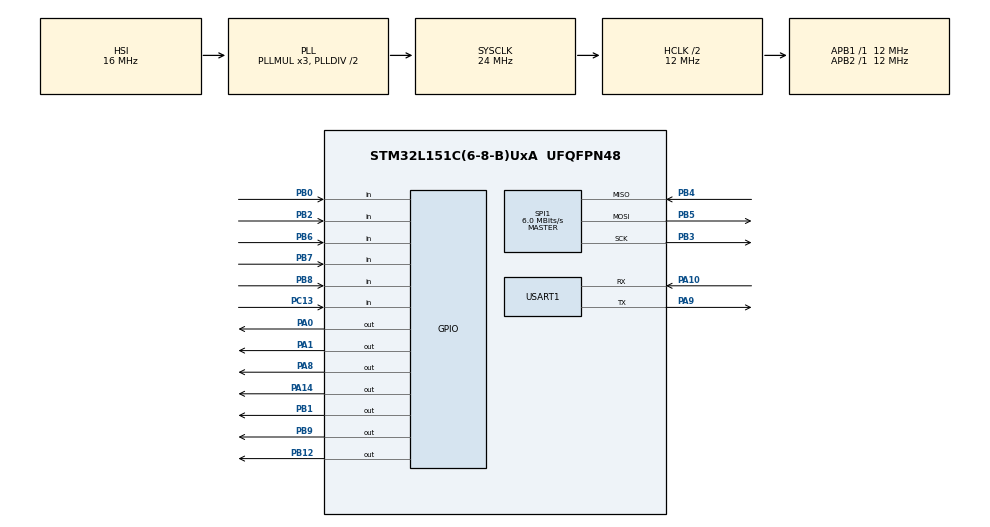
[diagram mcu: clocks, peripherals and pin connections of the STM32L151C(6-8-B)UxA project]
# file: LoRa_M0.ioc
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Dma.Request0=USART1_RX
Dma.USART1_RX.0.Direction=DMA_PERIPH_TO_MEMORY
Dma.USART1_RX.0.Instance=DMA1_Channel5
Dma.USART1_RX.0.MemDataAlignment=DMA_MDATAALIGN_BYTE
Dma.USART1_RX.0.MemInc=DMA_MINC_ENABLE
Dma.USART1_RX.0.Mode=DMA_NORMAL
Dma.USART1_RX.0.PeriphDataAlignment=DMA_PDATAALIGN_BYTE
Dma.USART1_RX.0.PeriphInc=DMA_PINC_DISABLE
Dma.USART1_RX.0.Priority=DMA_PRIORITY_LOW
Mcu.Family=STM32L1
Mcu.Name=STM32L151C(6-8-B)UxA
Mcu.Package=UFQFPN48
NVIC.DMA1_Channel5_IRQn=true\:0\:0\:false\:false\:true\:false\:true
NVIC.PriorityGroup=NVIC_PRIORITYGROUP_4
PA0-WKUP1.Signal=GPIO_Output
PA1.Signal=GPIO_Output
PA10.Mode=Asynchronous
PA10.Signal=USART1_RX
PA14.Signal=GPIO_Output
PA8.Signal=GPIO_Output
PA9.Mode=Asynchronous
PA9.Signal=USART1_TX
PB0.Signal=GPIO_Input
PB1.Signal=GPIO_Output
PB12.Signal=GPIO_Output
PB2.Signal=GPIO_Input
PB3.Mode=Full_Duplex_Master
PB3.Signal=SPI1_SCK
PB4.Mode=Full_Duplex_Master
PB4.Signal=SPI1_MISO
PB5.Mode=Full_Duplex_Master
PB5.Signal=SPI1_MOSI
PB6.Signal=GPIO_Input
PB7.Signal=GPIO_Input
PB8.Signal=GPIO_Input
PB9.GPIO_Speed=GPIO_SPEED_FREQ_LOW
PB9.Signal=GPIO_Output
PC13-WKUP2.Signal=GPIO_Input
ProjectManager.HeapSize=0x200
ProjectManager.StackSize=0x400
ProjectManager.TargetToolchain=EWARM V8
RCC.AHBCLKDivider=RCC_SYSCLK_DIV2
RCC.AHBFreq_Value=12000000
RCC.APB1Freq_Value=12000000
RCC.APB1TimFreq_Value=12000000
RCC.APB2Freq_Value=12000000
RCC.APB2TimFreq_Value=12000000
RCC.HCLKFreq_Value=12000000
RCC.HSE_VALUE=24000000
RCC.HSI_VALUE=16000000
RCC.LSE_VALUE=32768
RCC.MSIClockRange=RCC_MSIRANGE_6
RCC.MSI_VALUE=4194000
RCC.SYSCLKFreq_VALUE=24000000
RCC.SYSCLKSource=RCC_SYSCLKSOURCE_PLLCLK
RCC.VCOOutputFreq_Value=48000000
SPI1.BaudRatePrescaler=SPI_BAUDRATEPRESCALER_2
SPI1.CalculateBaudRate=6.0 MBits/s
SPI1.Direction=SPI_DIRECTION_2LINES
SPI1.Mode=SPI_MODE_MASTER
SPI1.VirtualType=VM_MASTER
USART1.VirtualMode=VM_ASYNC
board=custom

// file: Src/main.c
/* USER CODE BEGIN Header */
/**
  ******************************************************************************
  * @file           : main.c
  * @brief          : Main program body
  ******************************************************************************
  * @attention
  *
  * <h2><center>&copy; Copyright (c) 2019 STMicroelectronics.
  * All rights reserved.</center></h2>
  *
  * This software component is licensed by ST under BSD 3-Clause license,
  * the "License"; You may not use this file except in compliance with the
  * License. You may obtain a copy of the License at:
  *                        opensource.org/licenses/BSD-3-Clause
  *
  ******************************************************************************
  */
/* USER CODE END Header */

#include "main.h"
#include "dma.h"
#include "spi.h"
#include "usart.h"
#include "gpio.h"
#include <stdio.h>

//sx1278
#include "radio.h"
#include "platform.h"
#include "sx1276-Hal.h"
#include "sx1276-LoRa.h"
#include "sx1276-LoRaMisc.h"

void SystemClock_Config(void);

int main(void)
{
  /* USER CODE BEGIN 1 */
  uint8_t RegVersion = 0;

  /* USER CODE END 1 */

  /* MCU Configuration--------------------------------------------------------*/

  /* Reset of all peripherals, Initializes the Flash interface and the Systick. */
  HAL_Init();

  /* Configure the system clock */
  SystemClock_Config();

  /* Initialize all configured peripherals */
  MX_GPIO_Init();
  MX_DMA_Init();
 // printf("haha");
  MX_SPI1_Init();
  MX_USART1_UART_Init();

  /* Infinite loop */
  /* USER CODE BEGIN WHILE */

//-----------------------------------------------------------
  HAL_GPIO_WritePin(GPIOA, GPIO_PIN_1, GPIO_PIN_RESET);
//  printf("LoRa Test1\r\n");

  SX1276Read( REG_LR_VERSION, &RegVersion );
  if(RegVersion == 0x12)
  {
    printf("LoRa read OK\r\n");
    printf("LoRa RegVersion = %d\r\n", RegVersion);
  }
  else
  {
    printf("LoRa read ERROR\r\n");
    printf("LoRa RegVersion = %d\r\n", RegVersion);
  }

//-----------------------------------------------------------
  while (1)
  {
    /* USER CODE END WHILE */

  }
}

void SystemClock_Config(void)
{
  RCC_OscInitTypeDef RCC_OscInitStruct = {0};
  RCC_ClkInitTypeDef RCC_ClkInitStruct = {0};

  /** Configure the main internal regulator output voltage
  */
  __HAL_PWR_VOLTAGESCALING_CONFIG(PWR_REGULATOR_VOLTAGE_SCALE1);
  /** Initializes the CPU, AHB and APB busses clocks
  */
  RCC_OscInitStruct.OscillatorType = RCC_OSCILLATORTYPE_HSI;
  RCC_OscInitStruct.HSIState = RCC_HSI_ON;
  RCC_OscInitStruct.HSICalibrationValue = RCC_HSICALIBRATION_DEFAULT;
  RCC_OscInitStruct.PLL.PLLState = RCC_PLL_ON;
  RCC_OscInitStruct.PLL.PLLSource = RCC_PLLSOURCE_HSI;
  RCC_OscInitStruct.PLL.PLLMUL = RCC_PLL_MUL3;
  RCC_OscInitStruct.PLL.PLLDIV = RCC_PLL_DIV2;
  if (HAL_RCC_OscConfig(&RCC_OscInitStruct) != HAL_OK)
  {
    Error_Handler();
  }
  /** Initializes the CPU, AHB and APB busses clocks
  */
  RCC_ClkInitStruct.ClockType = RCC_CLOCKTYPE_HCLK|RCC_CLOCKTYPE_SYSCLK
                              |RCC_CLOCKTYPE_PCLK1|RCC_CLOCKTYPE_PCLK2;
  RCC_ClkInitStruct.SYSCLKSource = RCC_SYSCLKSOURCE_PLLCLK;
  RCC_ClkInitStruct.AHBCLKDivider = RCC_SYSCLK_DIV2;
  RCC_ClkInitStruct.APB1CLKDivider = RCC_HCLK_DIV1;
  RCC_ClkInitStruct.APB2CLKDivider = RCC_HCLK_DIV1;

  if (HAL_RCC_ClockConfig(&RCC_ClkInitStruct, FLASH_LATENCY_0) != HAL_OK)
  {
    Error_Handler();
  }
}

void Error_Handler(void)
{
  /* USER CODE BEGIN Error_Handler_Debug */
  /* User can add his own implementation to report the HAL error return state */

//  while(1);

  /* USER CODE END Error_Handler_Debug */
}

//重定向串口
int fputc(int c, FILE *stream)
{
    USART1->DR = c;//将c赋给串口1的DR寄存器，即重定向到串口，也可以是其他的接口
    while(!(USART1->SR & (1 << 7))){};//等待数据发送完成
    return c;
}

/************************ (C) COPYRIGHT STMicroelectronics *****END OF FILE****/
